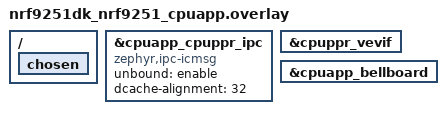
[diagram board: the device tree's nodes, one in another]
/*
 * Copyright (c) 2026 Nordic Semiconductor ASA
 * SPDX-License-Identifier: LicenseRef-Nordic-5-Clause
 */

ipc0: &cpuapp_cpuppr_ipc {
	compatible = "zephyr,ipc-icmsg";
	unbound = "enable";
	/delete-property/ tx-blocks;
	/delete-property/ rx-blocks;
	dcache-alignment = <32>;
	status = "okay";
};

&cpuppr_vevif {
	status = "okay";
};

&cpuapp_bellboard {
	status = "okay";
};

/ {
	chosen {
		/delete-property/ zephyr,bt-hci;
	};
};
